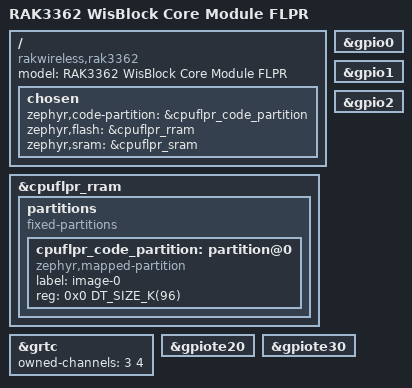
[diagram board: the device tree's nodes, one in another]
/*
 * Copyright (c) 2026 RAKwireless Technology Limited
 * SPDX-License-Identifier: Apache-2.0
 */

/dts-v1/;
#include <vendor/nordic/nrf54l15_cpuflpr.dtsi>

/ {
	model = "RAK3362 WisBlock Core Module FLPR";
	compatible = "rakwireless,rak3362";

	chosen {
		zephyr,code-partition = &cpuflpr_code_partition;
		zephyr,flash = &cpuflpr_rram;
		zephyr,sram = &cpuflpr_sram;
	};
};

&cpuflpr_rram {
	partitions {
		compatible = "fixed-partitions";
		#address-cells = <1>;
		#size-cells = <1>;
		ranges;

		cpuflpr_code_partition: partition@0 {
			label = "image-0";
			compatible = "zephyr,mapped-partition";
			reg = <0x0 DT_SIZE_K(96)>;
		};
	};
};

&grtc {
	owned-channels = <3 4>;
	status = "okay";
};

&gpio0 {
	status = "okay";
};

&gpio1 {
	status = "okay";
};

&gpio2 {
	status = "okay";
};

&gpiote20 {
	status = "okay";
};

&gpiote30 {
	status = "okay";
};
